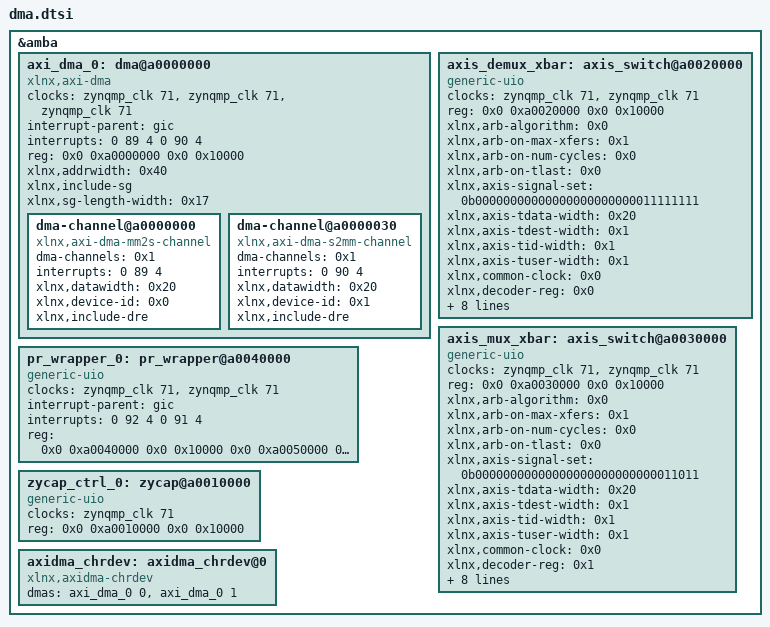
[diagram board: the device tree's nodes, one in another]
/*
 * CAUTION: This file is automatically generated by Xilinx.
 * Version:  
 * Today is: Mon Apr 26 10:38:00 2021
 */


/dts-v1/;
/plugin/;
/ {
	// fragment@0 {
	// 	target = <&fpga_full>;
	// 	overlay0: __overlay__ {
	// 		#address-cells = <2>;
	// 		#size-cells = <2>;
	// 		firmware-name = "dma_sobel.bit.bin";
	// 		resets = <&zynqmp_reset 116>;
	// 	};
	// };
	// fragment@1 {
	// 	target = <&amba>;
	// 	overlay1: __overlay__ {
	// 		afi0: afi0 {
	// 			compatible = "xlnx,afi-fpga";
	// 			config-afi = < 0 1>, <1 1>, <2 0>, <3 0>, <4 1>, <5 1>, <6 0>, <7 0>, <8 0>, <9 0>, <10 0>, <11 0>, <12 0>, <13 0>, <14 0x500>, <15 0x000>;
	// 		};
	// 		clocking0: clocking0 {
	// 			#clock-cells = <0>;
	// 			assigned-clock-rates = <100000000>;
	// 			assigned-clocks = <&zynqmp_clk 71>;
	// 			clock-output-names = "fabric_clk";
	// 			clocks = <&zynqmp_clk 71>;
	// 			compatible = "xlnx,fclk";
	// 		};
	// 	};
	// };
	fragment@2 {
		target = <&amba>;
		overlay2: __overlay__ {
			#address-cells = <2>;
			#size-cells = <2>;
			axi_dma_0: dma@a0000000 {
				#dma-cells = <1>;
				clock-names = "s_axi_lite_aclk", "m_axi_mm2s_aclk", "m_axi_s2mm_aclk";
				clocks = <&zynqmp_clk 71>, <&zynqmp_clk 71>, <&zynqmp_clk 71>;
				compatible = "xlnx,axi-dma", "xlnx,axi-dma-7.1", "xlnx,axi-dma-1.00.a";
				interrupt-names = "mm2s_introut", "s2mm_introut";
				interrupt-parent = <&gic>;
				interrupts = <0 89 4 0 90 4>;
				reg = <0x0 0xa0000000 0x0 0x10000>;
				xlnx,addrwidth = <0x40>;
				xlnx,include-sg ;
				xlnx,sg-length-width = <0x17>;
				dma-channel@a0000000 {
					compatible = "xlnx,axi-dma-mm2s-channel";
					dma-channels = <0x1>;
					interrupts = <0 89 4>;
					xlnx,datawidth = <0x20>;
					xlnx,device-id = <0x0>;
					xlnx,include-dre ;
				};
				dma-channel@a0000030 {
					compatible = "xlnx,axi-dma-s2mm-channel";
					dma-channels = <0x1>;
					interrupts = <0 90 4>;
					xlnx,datawidth = <0x20>;
					xlnx,device-id = <0x1>;
					xlnx,include-dre ;
				};
			};
			// misc_clk_0: misc_clk_0 {
			// 	#clock-cells = <0>;
			// 	clock-frequency = <200000000>;
			// 	compatible = "fixed-clock";
			// };
			axis_demux_xbar: axis_switch@a0020000 {
				clock-names = "aclk", "s_axi_ctrl_aclk";
				clocks = <&zynqmp_clk 71>, <&zynqmp_clk 71>;
				compatible = "generic-uio";
				reg = <0x0 0xa0020000 0x0 0x10000>;
				xlnx,arb-algorithm = <0x0>;
				xlnx,arb-on-max-xfers = <0x1>;
				xlnx,arb-on-num-cycles = <0x0>;
				xlnx,arb-on-tlast = <0x0>;
				xlnx,axis-signal-set = "0b00000000000000000000000011111111";
				xlnx,axis-tdata-width = <0x20>;
				xlnx,axis-tdest-width = <0x1>;
				xlnx,axis-tid-width = <0x1>;
				xlnx,axis-tuser-width = <0x1>;
				xlnx,common-clock = <0x0>;
				xlnx,decoder-reg = <0x0>;
				xlnx,include-arbiter = <0x1>;
				xlnx,log-si-slots = <0x2>;
				xlnx,num-mi-slots = <0x1>;
				xlnx,num-si-slots = <0x3>;
				xlnx,output-reg = <0x0>;
				xlnx,routing-mode = <0x1>;
				xlnx,s-axi-ctrl-addr-width = <0x7>;
				xlnx,s-axi-ctrl-data-width = <0x20>;
			};
			axis_mux_xbar: axis_switch@a0030000 {
				clock-names = "aclk", "s_axi_ctrl_aclk";
				clocks = <&zynqmp_clk 71>, <&zynqmp_clk 71>;
				compatible = "generic-uio";
				reg = <0x0 0xa0030000 0x0 0x10000>;
				xlnx,arb-algorithm = <0x0>;
				xlnx,arb-on-max-xfers = <0x1>;
				xlnx,arb-on-num-cycles = <0x0>;
				xlnx,arb-on-tlast = <0x0>;
				xlnx,axis-signal-set = "0b00000000000000000000000000011011";
				xlnx,axis-tdata-width = <0x20>;
				xlnx,axis-tdest-width = <0x1>;
				xlnx,axis-tid-width = <0x1>;
				xlnx,axis-tuser-width = <0x1>;
				xlnx,common-clock = <0x0>;
				xlnx,decoder-reg = <0x1>;
				xlnx,include-arbiter = <0x1>;
				xlnx,log-si-slots = <0x1>;
				xlnx,num-mi-slots = <0x3>;
				xlnx,num-si-slots = <0x1>;
				xlnx,output-reg = <0x0>;
				xlnx,routing-mode = <0x1>;
				xlnx,s-axi-ctrl-addr-width = <0x7>;
				xlnx,s-axi-ctrl-data-width = <0x20>;
			};
			pr_wrapper_0: pr_wrapper@a0040000 {
				clock-names = "ap_clk_0", "ap_clk_1";
				clocks = <&zynqmp_clk 71>, <&zynqmp_clk 71>;
				compatible = "generic-uio";
				interrupt-names = "interrupt_0", "interrupt_1";
				interrupt-parent = <&gic>;
				interrupts = <0 92 4 0 91 4>;
				reg = <0x0 0xa0040000 0x0 0x10000 0x0 0xa0050000 0x0 0x10000>;
			};
			zycap_ctrl_0: zycap@a0010000 {
				clock-names = "s_axi_lite_aclk";
				clocks = <&zynqmp_clk 71>;
				compatible = "generic-uio";
				reg = <0x0 0xa0010000 0x0 0x10000>;
			};
		};
	};
     fragment@3 {
        target = <&amba>;
        overlay3: __overlay__ {
            axidma_chrdev: axidma_chrdev@0 {
                compatible = "xlnx,axidma-chrdev";
                dmas = <&axi_dma_0 0 &axi_dma_0 1>;
                dma-names = "tx_channel", "rx_channel";
            };
            // udmabuf_0: udmabuf@0 {
            //     compatible = "ikwzm,u-dma-buf";
            //     device-name = "udmabuf0";
            //     minor-number = <0>;
            //     size = <0x00100000>;
            // };
        };
	};
};
